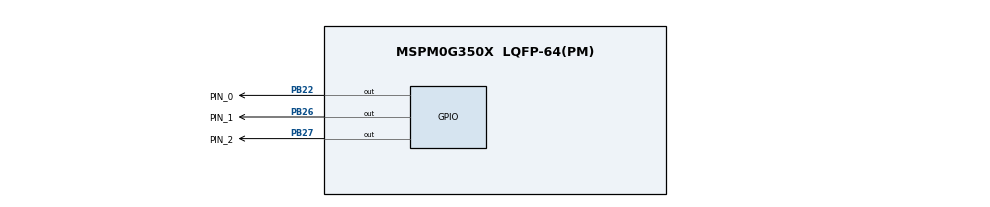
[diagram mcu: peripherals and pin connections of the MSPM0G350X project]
/**
 * @cliArgs --device "MSPM0G350X" --part "Default" --package "LQFP-64(PM)" --product "mspm0_sdk@2.09.00.02"
 * @versions {"tool":"1.25.0+4268"}
 */

/**
 * Import the modules used in this configuration.
 */
const GPIO   = scripting.addModule("/ti/driverlib/GPIO", {}, false);
const GPIO1  = GPIO.addInstance();
const GPIO2  = GPIO.addInstance();
const GPIO3  = GPIO.addInstance();
const SYSCTL = scripting.addModule("/ti/driverlib/SYSCTL");

/**
 * Write custom configuration values to the imported modules.
 */
GPIO1.$name                          = "GPIO_USER_LED_1";
GPIO1.port                           = "PORTB";
GPIO1.associatedPins[0].$name        = "PIN_0";
GPIO1.associatedPins[0].initialValue = "SET";
GPIO1.associatedPins[0].pin.$assign  = "PB22";

const Board = scripting.addModule("/ti/driverlib/Board", {}, false);

GPIO2.$name                         = "GPIO_USER_LED_2";
GPIO2.port                          = "PORTB";
GPIO2.associatedPins[0].$name       = "PIN_1";
GPIO2.associatedPins[0].pin.$assign = "PB26";

GPIO3.$name                         = "GPIO_USER_LED_3";
GPIO3.associatedPins[0].$name       = "PIN_2";
GPIO3.associatedPins[0].pin.$assign = "PB27";

SYSCTL.forceDefaultClkConfig = true;

/**
 * Pinmux solution for unlocked pins/peripherals. This ensures that minor changes to the automatic solver in a future
 * version of the tool will not impact the pinmux you originally saw.  These lines can be completely deleted in order to
 * re-solve from scratch.
 */
Board.peripheral.$suggestSolution          = "DEBUGSS";
Board.peripheral.swclkPin.$suggestSolution = "PA20";
Board.peripheral.swdioPin.$suggestSolution = "PA19";
SYSCTL.peripheral.$suggestSolution         = "SYSCTL";
